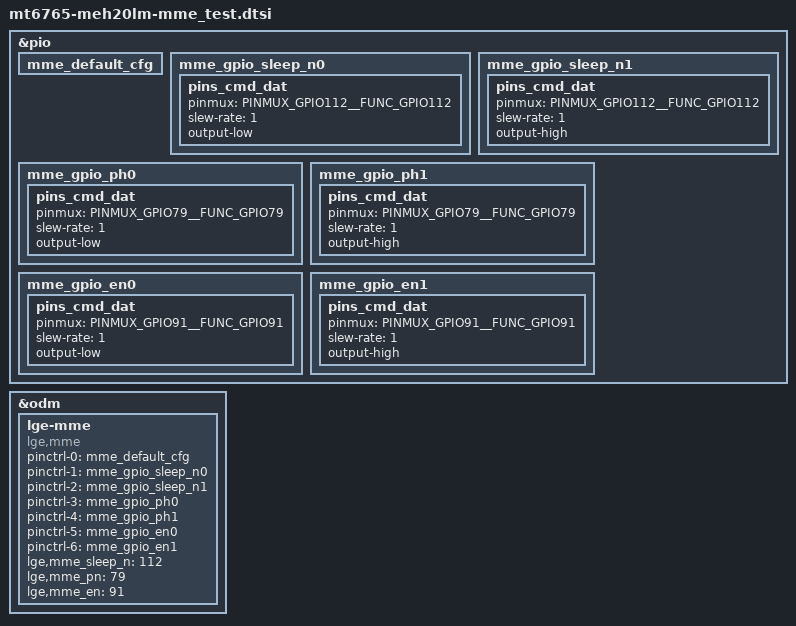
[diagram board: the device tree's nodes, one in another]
/*
 * LG Electronics HDK mme device tree source
 *
 * Copyright (c) 2017 LG Electronics Co., Ltd.
 *              http://www.lge.com
 *
 */

/**********************************************
 * MME driver bring up
 ********************************************/

/* All output lines were pulled down by PWM driver chipset internally. */
&pio {
    mme_default_cfg: mme_default_cfg {
    };

    mme_gpio_sleep_n0: mme_gpio_sleep_n0 {
        pins_cmd_dat {
            pinmux = <PINMUX_GPIO112__FUNC_GPIO112>;
            slew-rate = <1>; /* direction 0:in, 1:out */
            output-low;
        };
    };

    mme_gpio_sleep_n1: mme_gpio_sleep_n1 {
        pins_cmd_dat {
            pinmux = <PINMUX_GPIO112__FUNC_GPIO112>;
            slew-rate = <1>; /* direction 0:in, 1:out */
            output-high;
        };
    };

    mme_gpio_ph0: mme_gpio_ph0 {
        pins_cmd_dat {
            pinmux = <PINMUX_GPIO79__FUNC_GPIO79>;
            slew-rate = <1>; /* direction 0:in, 1:out */
            output-low;
        };
    };

    mme_gpio_ph1: mme_gpio_ph1 {
        pins_cmd_dat {
            pinmux = <PINMUX_GPIO79__FUNC_GPIO79>;
            slew-rate = <1>; /* direction 0:in, 1:out */
            output-high;
        };
    };

    mme_gpio_en0: mme_gpio_en0 {
        pins_cmd_dat {
            pinmux = <PINMUX_GPIO91__FUNC_GPIO91>;
            slew-rate = <1>; /* direction 0:in, 1:out */
            output-low;
        };
    };

    mme_gpio_en1: mme_gpio_en1 {
        pins_cmd_dat {
            pinmux = <PINMUX_GPIO91__FUNC_GPIO91>;
            slew-rate = <1>; /* direction 0:in, 1:out */
            output-high;
        };
    };
};

&odm {
    lge-mme {
        compatible = "lge,mme";

        pinctrl-names = "default", "mme_gpio_sleep_n0", "mme_gpio_sleep_n1",
                               "mme_gpio_ph0", "mme_gpio_ph1", "mme_gpio_en0", "mme_gpio_en1";
        pinctrl-0 = <&mme_default_cfg>;
        pinctrl-1 = <&mme_gpio_sleep_n0>;
        pinctrl-2 = <&mme_gpio_sleep_n1>;
        pinctrl-3 = <&mme_gpio_ph0>;
        pinctrl-4 = <&mme_gpio_ph1>;
        pinctrl-5 = <&mme_gpio_en0>;
        pinctrl-6 = <&mme_gpio_en1>;

        lge,mme_sleep_n = <112>;
        lge,mme_pn = <79>;
        lge,mme_en = <91>;

        status = "okay";
    };
};
